# SF32LB58x register map
File version: 1.0
CPU: CM33 r0p1, little endian, MPU, FPU, 3 interrupt priority bits
Registers are 32-bit, read-write, reset 0x0 unless marked. A register's access mark holds for its fields unless they carry their own. Offsets are from the block's base; [hi:lo] are bit positions; {n}, {i} and the like mark numbered series; 'fields as' and 'values as' point back to an identical list.

## DMAC1
Base 0x40001000
Same registers: DMAC2 0x40018000, DMAC3 0x50001000
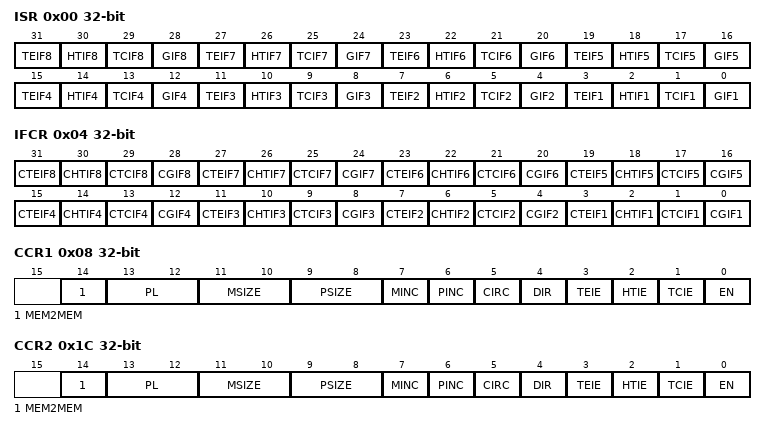
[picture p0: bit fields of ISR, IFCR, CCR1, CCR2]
0x00 ISR
  [4n-1] TEIF{n} (n=2..8) — channel transfer error flag
  [4n-2] HTIF{n} (n=2..8) — channel half transfer flag
  [4n-3] TCIF{n} (n=2..8) — channel transfer complete flag
  [4n-4] GIF{n} (n=2..8) — channel global interrupt flag
  [3] TEIF1 — channel transfer error flag. Set when bus error detected. Cleared when write 1 to CTEIF or CGIF.
  [2] HTIF1 — channel half transfer flag. Set when half NDT are transferred. Cleared when write 1 to CHTIF or CGIF.
  [1] TCIF1 — channel transfer complete flag. Set when all NDT are transferred. Cleared when write 1 to CTCIF or CGIF.
  [0] GIF1 — channel global interrupt flag. Set when any of TEIF/HTIF/TCIF asserted. Cleared when TEIF/HTIF/TCIF all cleared.
0x04 IFCR
  [4n-1] CTEIF{n} (n=2..8) — CTEIF, transfer error flag clear
  [4n-2] CHTIF{n} (n=2..8) — CHTIF, half transfer flag clear
  [4n-3] CTCIF{n} (n=2..8) — CTCIF, transfer complete flag clear
  [4n-4] CGIF{n} (n=2..8) — CGIF, global interrupt flag clear
  [3] CTEIF1 — CTEIF, transfer error flag clear. Write 1 to clear TEIF.
  [2] CHTIF1 — CHTIF, half transfer flag clear. Write 1 to clear HTIF.
  [1] CTCIF1 — CTCIF, transfer complete flag clear. Write 1 to clear TCIF.
  [0] CGIF1 — CGIF, global interrupt flag clear. Write 1 to clear all TEIF/HTIF/TCIF.
0x08 CCR1
  [14] MEM2MEM — memory-to-memory mode 0: disabled 1: enabled
  [13:12] PL — priority level 00: low 01: medium 10: high 11: very high
  [11:10] MSIZE — memory size Defines the data size of each DMA transfer to the identified memory. In memory-to-memory mode, this field identifies the memory source if DIR = 1 and the memory destination if DIR = 0. In peripheral-to-peripheral mode, this field identifies the peripheral source if DIR = 1 and the peripheral destination if DIR = 0. 00: 8 bits 01: 16 bits 10: 32 bits 11: reserved
  [9:8] PSIZE — peripheral size Defines the data size of each DMA transfer to the identified peripheral. In memory-to-memory mode, this field identifies the memory destination if DIR = 1 and the memory source if DIR = 0. In peripheral-to-peripheral mode, this field identifies the peripheral destination if DIR = 1 and the peripheral source if DIR = 0. 00: 8 bits 01: 16 bits 10: 32 bits 11: reserved
  [7] MINC — memory increment mode Defines the increment mode for each DMA transfer to the identified memory. In memory-to-memory mode, this field identifies the memory source if DIR = 1 and the memory destination if DIR = 0. In peripheral-to-peripheral mode, this field identifies the peripheral source if DIR = 1 and the peripheral destination if DIR = 0. 0: disabled 1: enabled
  [6] PINC — peripheral increment mode Defines the increment mode for each DMA transfer to the identified peripheral. n memory-to-memory mode, this field identifies the memory destination if DIR = 1 and the memory source if DIR = 0. In peripheral-to-peripheral mode, this field identifies the peripheral destination if DIR = 1 and the peripheral source if DIR = 0. 0: disabled 1: enabled
  [5] CIRC — circular mode 0: disabled 1: enabled
  [4] DIR — data transfer direction This bit must be set only in memory-to-peripheral and peripheral-to-memory modes. 0: read from peripheral Source attributes are defined by PSIZE and PINC, plus the CPARx register. This is still valid in a memory-to-memory mode. Destination attributes are defined by MSIZE and MINC, plus the CM0ARx register. This is still valid in a peripheral-to-peripheral mode. 1: read from memory Destination attributes are defined by PSIZE and PINC, plus the CPARx register. This is still valid in a memory-to-memory mode. Source attributes are defined by MSIZE and MINC, plus the CM0ARx register. This is still valid in a peripheral-to-peripheral mode.
  [3] TEIE — transfer error interrupt enable 0: disabled 1: enabled
  [2] HTIE — half transfer interrupt enable 0: disabled 1: enabled
  [1] TCIE — transfer complete interrupt enable 0: disabled 1: enabled
  [0] EN — channel enable When a channel transfer error occurs, this bit is cleared by hardware. It can not be set again by software (channel x re-activated) until the TEIFx bit of the ISR register is cleared (by setting the CTEIFx bit of the IFCR register). 0: disabled 1: enabled
0x0C CNDTR1
  [15:0] NDT — number of data to transfer (0 to 2^16 - 1) This field is updated by hardware when the channel is enabled: It is decremented after each single DMA 'read followed by write' transfer, indicating the remaining amount of data items to transfer. It is kept at zero when the programmed amount of data to transfer is reached, if the channel is not in circular mode (CIRC = 0 in the CCRx register). It is reloaded automatically by the previously programmed value, when the transfer is complete, if the channel is in circular mode (CIRC = 1). If this field is zero, no transfer can be served whatever the channel status (enabled or not).
0x10 CPAR1
  [31:0] PA — peripheral address It contains the base address of the peripheral data register from/to which the data will be read/written. In memory-to-memory mode, this register identifies the memory destination address if DIR = 1 and the memory source address if DIR = 0. In peripheral-to-peripheral mode, this register identifies the peripheral destination address DIR = 1 and the peripheral source address if DIR = 0.
0x14 CM0AR1
  [31:0] MA — memory address It contains the base address of the memory from/to which the data will be read/written. In memory-to-memory mode, this register identifies the memory source address if DIR = 1 and the memory destination address if DIR = 0. In peripheral-to-peripheral mode, this register identifies the peripheral source address DIR = 1 and the peripheral destination address if DIR = 0.
{0x4+0x14*i} CBSR{i} (i=1..6)
  [7:0] BS — burst size in non-m2m mode When BS>1, DMA will transfer for BS times for each request if left NDT is larger than BS, or else transfer for left NDT times. When BS=0 or 1, DMA will always do single transfer for each request. In memory-to-memory mode, BS is ignored.
0x1C CCR2
  fields as CCR1
0x20 CNDTR2
  fields as CNDTR1
0x24 CPAR2
  fields as CPAR1
{0x0+0x14*i} CM0AR{i} (i=2..8)
  [31:0] MA — peripheral address It contains the base address of the memory from/to which the data will be read/written. In memory-to-memory mode, this register identifies the memory source address if DIR = 1 and the memory destination address if DIR = 0. In peripheral-to-peripheral mode, this register identifies the peripheral source address DIR = 1 and the peripheral destination address if DIR = 0.
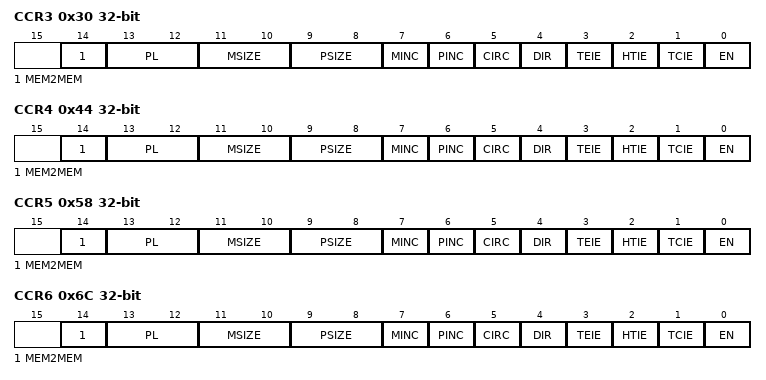
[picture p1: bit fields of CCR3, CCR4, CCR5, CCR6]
0x30 CCR3
  fields as CCR1
0x34 CNDTR3
  fields as CNDTR1
0x38 CPAR3
  fields as CPAR1
0x44 CCR4
  fields as CCR1
0x48 CNDTR4
  fields as CNDTR1
0x4C CPAR4
  fields as CPAR1
0x58 CCR5
  fields as CCR1
0x5C CNDTR5
  fields as CNDTR1
0x60 CPAR5
  fields as CPAR1
0x6C CCR6
  fields as CCR1
0x70 CNDTR6
  fields as CNDTR1
0x74 CPAR6
  fields as CPAR1
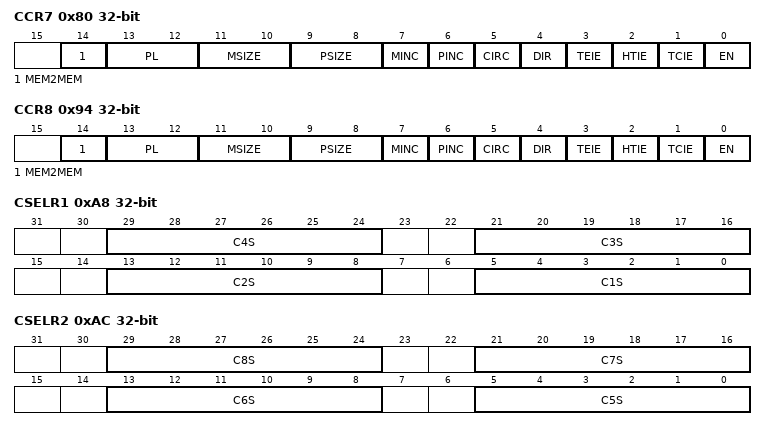
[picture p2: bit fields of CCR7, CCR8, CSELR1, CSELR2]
0x80 CCR7
  fields as CCR1
0x84 CNDTR7
  fields as CNDTR1
0x88 CPAR7
  fields as CPAR1
0x90 CBSR7
  [7:0] BS — burst size in non memory-to-memory mode When BS>1, DMA will transfer for BS times for each request if left NDT is larger than BS, or else transfer for left NDT times. When BS=0 or 1, DMA will always do single transfer for each request. In memory-to-memory mode, BS is ignored.
0x94 CCR8
  fields as CCR1
0x98 CNDTR8
  fields as CNDTR1
0x9C CPAR8
  fields as CPAR1
0xA4 CBSR8
  fields as CBSR1
0xA8 CSELR1
  [8n-3:8n-8] C{n}S (n=1..4) — DMA channel {n} selection
0xAC CSELR2
  [8n-35:8n-40] C{n}S (n=5..8) — DMA channel {n} selection
